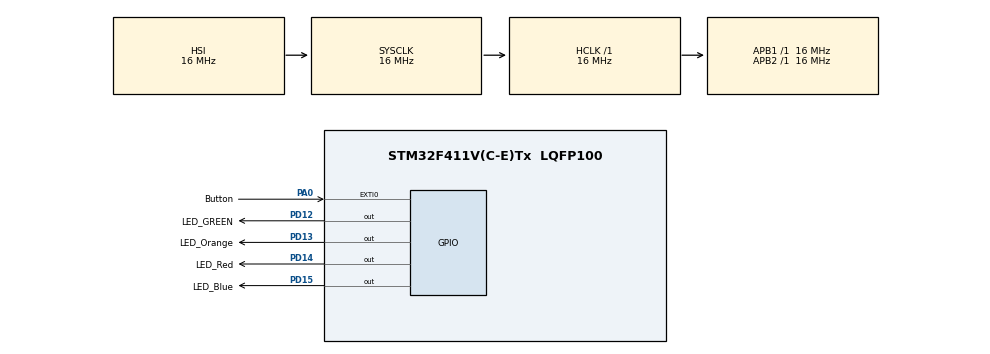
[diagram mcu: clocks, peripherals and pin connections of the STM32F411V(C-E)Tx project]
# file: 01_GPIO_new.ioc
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Mcu.Family=STM32F4
Mcu.Name=STM32F411V(C-E)Tx
Mcu.Package=LQFP100
NVIC.EXTI0_IRQn=true\:0\:0\:false\:false\:true
NVIC.PriorityGroup=NVIC_PRIORITYGROUP_4
PA0-WKUP.GPIO_Label=Button
PA0-WKUP.GPIO_ModeDefaultEXTI=GPIO_MODE_IT_RISING_FALLING
PA0-WKUP.Signal=GPXTI0
PD12.GPIO_Label=LED_GREEN
PD12.Signal=GPIO_Output
PD13.GPIO_Label=LED_Orange
PD13.Signal=GPIO_Output
PD14.GPIO_Label=LED_Red
PD14.Signal=GPIO_Output
PD15.GPIO_Label=LED_Blue
PD15.Signal=GPIO_Output
ProjectManager.HeapSize=0x200
ProjectManager.StackSize=0x400
ProjectManager.TargetToolchain=SW4STM32
RCC.AHBFreq_Value=16000000
RCC.APB1Freq_Value=16000000
RCC.APB2Freq_Value=16000000
RCC.CortexFreq_Value=16000000
RCC.HSE_VALUE=25000000
RCC.HSI_VALUE=16000000
RCC.LSE_VALUE=32768
RCC.SYSCLKFreq_VALUE=16000000
RCC.VCOOutputFreq_Value=192000000
board=01_GPIO_new

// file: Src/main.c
/**
  ******************************************************************************
  * File Name          : main.c
  * Description        : Main program body
  ******************************************************************************
  *
  * COPYRIGHT(c) 2017 STMicroelectronics
  *
  * Redistribution and use in source and binary forms, with or without modification,
  * are permitted provided that the following conditions are met:
  *   1. Redistributions of source code must retain the above copyright notice,
  *      this list of conditions and the following disclaimer.
  *   2. Redistributions in binary form must reproduce the above copyright notice,
  *      this list of conditions and the following disclaimer in the documentation
  *      and/or other materials provided with the distribution.
  *   3. Neither the name of STMicroelectronics nor the names of its contributors
  *      may be used to endorse or promote products derived from this software
  *      without specific prior written permission.
  *
  * THIS SOFTWARE IS PROVIDED BY THE COPYRIGHT HOLDERS AND CONTRIBUTORS "AS IS"
  * AND ANY EXPRESS OR IMPLIED WARRANTIES, INCLUDING, BUT NOT LIMITED TO, THE
  * IMPLIED WARRANTIES OF MERCHANTABILITY AND FITNESS FOR A PARTICULAR PURPOSE ARE
  * DISCLAIMED. IN NO EVENT SHALL THE COPYRIGHT HOLDER OR CONTRIBUTORS BE LIABLE
  * FOR ANY DIRECT, INDIRECT, INCIDENTAL, SPECIAL, EXEMPLARY, OR CONSEQUENTIAL
  * DAMAGES (INCLUDING, BUT NOT LIMITED TO, PROCUREMENT OF SUBSTITUTE GOODS OR
  * SERVICES; LOSS OF USE, DATA, OR PROFITS; OR BUSINESS INTERRUPTION) HOWEVER
  * CAUSED AND ON ANY THEORY OF LIABILITY, WHETHER IN CONTRACT, STRICT LIABILITY,
  * OR TORT (INCLUDING NEGLIGENCE OR OTHERWISE) ARISING IN ANY WAY OUT OF THE USE
  * OF THIS SOFTWARE, EVEN IF ADVISED OF THE POSSIBILITY OF SUCH DAMAGE.
  *
  ******************************************************************************
  */
#include "main.h"
#include "stm32f4xx_hal.h"

/* USER CODE BEGIN PV */
/* Private variables ---------------------------------------------------------*/

/* USER CODE END PV */

void SystemClock_Config(void);
void Error_Handler(void);
static void MX_GPIO_Init(void);

/* USER CODE BEGIN PFP */
/* Private function prototypes -----------------------------------------------*/
void HAL_GPIO_EXTI_Callback(uint16_t GPIO_Pin) {
//	static uint8_t counter = 1;
	static uint8_t state = 1;

	if (GPIO_Pin == Button_Pin) {
//		switch(counter) {
//		case 1:
//			HAL_GPIO_WritePin(LED_Blue_GPIO_Port, LED_Blue_Pin, HAL_GPIO_ReadPin(Button_GPIO_Port, Button_Pin));
//			break;
//		case 2:
//			HAL_GPIO_WritePin(LED_Green_GPIO_Port, LED_Green_Pin, HAL_GPIO_ReadPin(Button_GPIO_Port, Button_Pin));
//			break;
//		case 3:
//			HAL_GPIO_WritePin(LED_Orange_GPIO_Port, LED_Orange_Pin, HAL_GPIO_ReadPin(Button_GPIO_Port, Button_Pin));
//			break;
//		case 4:
//			HAL_GPIO_WritePin(LED_Red_GPIO_Port, LED_Red_Pin, HAL_GPIO_ReadPin(Button_GPIO_Port, Button_Pin));
//			break;
//		default:
//			counter = 0;
//			break;
//		}
//		counter++;

//		if (state == 1)
//			HAL_GPIO_WritePin(LED_Blue_GPIO_Port, LED_Blue_Pin, GPIO_PIN_SET);
//		else if (state == 2)
//			HAL_GPIO_WritePin(LED_Green_GPIO_Port, LED_Green_Pin, GPIO_PIN_SET);
//		else if (state == 3)
//			HAL_GPIO_WritePin(LED_Orange_GPIO_Port, LED_Orange_Pin, GPIO_PIN_SET);
//		else if (state == 4)
//			HAL_GPIO_WritePin(LED_Red_GPIO_Port, LED_Red_Pin, GPIO_PIN_SET);

		if (state == 1) {
			HAL_GPIO_TogglePin(LED_Blue_GPIO_Port, LED_Blue_Pin);
		} else if (state == 2) {
			HAL_GPIO_TogglePin(LED_GREEN_GPIO_Port, LED_GREEN_Pin);
		} else if (state == 3) {
			HAL_GPIO_TogglePin(LED_Orange_GPIO_Port, LED_Orange_Pin);
		} else if (state == 4) {
			HAL_GPIO_TogglePin(LED_Red_GPIO_Port, LED_Red_Pin);
		}

		++state;
		if (state == 5) {
			state = 1;
		}

	}

}
/* USER CODE END PFP */

int main(void)
{

  /* MCU Configuration----------------------------------------------------------*/

  /* Reset of all peripherals, Initializes the Flash interface and the Systick. */
  HAL_Init();

  /* Configure the system clock */
  SystemClock_Config();

  /* Initialize all configured peripherals */
  MX_GPIO_Init();

  /* Infinite loop */
  while (1)
  {

  }

}

/** System Clock Configuration
*/
void SystemClock_Config(void)
{

  RCC_OscInitTypeDef RCC_OscInitStruct;
  RCC_ClkInitTypeDef RCC_ClkInitStruct;

    /**Configure the main internal regulator output voltage
    */
  __HAL_RCC_PWR_CLK_ENABLE();

  __HAL_PWR_VOLTAGESCALING_CONFIG(PWR_REGULATOR_VOLTAGE_SCALE1);

    /**Initializes the CPU, AHB and APB busses clocks
    */
  RCC_OscInitStruct.OscillatorType = RCC_OSCILLATORTYPE_HSI;
  RCC_OscInitStruct.HSIState = RCC_HSI_ON;
  RCC_OscInitStruct.HSICalibrationValue = 16;
  RCC_OscInitStruct.PLL.PLLState = RCC_PLL_NONE;
  if (HAL_RCC_OscConfig(&RCC_OscInitStruct) != HAL_OK)
  {
    Error_Handler();
  }

    /**Initializes the CPU, AHB and APB busses clocks
    */
  RCC_ClkInitStruct.ClockType = RCC_CLOCKTYPE_HCLK|RCC_CLOCKTYPE_SYSCLK
                              |RCC_CLOCKTYPE_PCLK1|RCC_CLOCKTYPE_PCLK2;
  RCC_ClkInitStruct.SYSCLKSource = RCC_SYSCLKSOURCE_HSI;
  RCC_ClkInitStruct.AHBCLKDivider = RCC_SYSCLK_DIV1;
  RCC_ClkInitStruct.APB1CLKDivider = RCC_HCLK_DIV1;
  RCC_ClkInitStruct.APB2CLKDivider = RCC_HCLK_DIV1;

  if (HAL_RCC_ClockConfig(&RCC_ClkInitStruct, FLASH_LATENCY_0) != HAL_OK)
  {
    Error_Handler();
  }

    /**Configure the Systick interrupt time
    */
  HAL_SYSTICK_Config(HAL_RCC_GetHCLKFreq()/1000);

    /**Configure the Systick
    */
  HAL_SYSTICK_CLKSourceConfig(SYSTICK_CLKSOURCE_HCLK);

  /* SysTick_IRQn interrupt configuration */
  HAL_NVIC_SetPriority(SysTick_IRQn, 0, 0);
}

/** Configure pins as
        * Analog
        * Input
        * Output
        * EVENT_OUT
        * EXTI
*/
static void MX_GPIO_Init(void)
{

  GPIO_InitTypeDef GPIO_InitStruct;

  /* GPIO Ports Clock Enable */
  __HAL_RCC_GPIOA_CLK_ENABLE();
  __HAL_RCC_GPIOD_CLK_ENABLE();

  /*Configure GPIO pin Output Level */
  HAL_GPIO_WritePin(GPIOD, LED_GREEN_Pin|LED_Orange_Pin|LED_Red_Pin|LED_Blue_Pin, GPIO_PIN_RESET);

  /*Configure GPIO pin : Button_Pin */
  GPIO_InitStruct.Pin = Button_Pin;
  GPIO_InitStruct.Mode = GPIO_MODE_IT_RISING_FALLING;
  GPIO_InitStruct.Pull = GPIO_NOPULL;
  HAL_GPIO_Init(Button_GPIO_Port, &GPIO_InitStruct);

  /*Configure GPIO pins : LED_GREEN_Pin LED_Orange_Pin LED_Red_Pin LED_Blue_Pin */
  GPIO_InitStruct.Pin = LED_GREEN_Pin|LED_Orange_Pin|LED_Red_Pin|LED_Blue_Pin;
  GPIO_InitStruct.Mode = GPIO_MODE_OUTPUT_PP;
  GPIO_InitStruct.Pull = GPIO_NOPULL;
  GPIO_InitStruct.Speed = GPIO_SPEED_FREQ_LOW;
  HAL_GPIO_Init(GPIOD, &GPIO_InitStruct);

  /* EXTI interrupt init*/
  HAL_NVIC_SetPriority(EXTI0_IRQn, 0, 0);
  HAL_NVIC_EnableIRQ(EXTI0_IRQn);

}

void Error_Handler(void)
{
  while(1)
  {
  }
}

/************************ (C) COPYRIGHT STMicroelectronics *****END OF FILE****/
